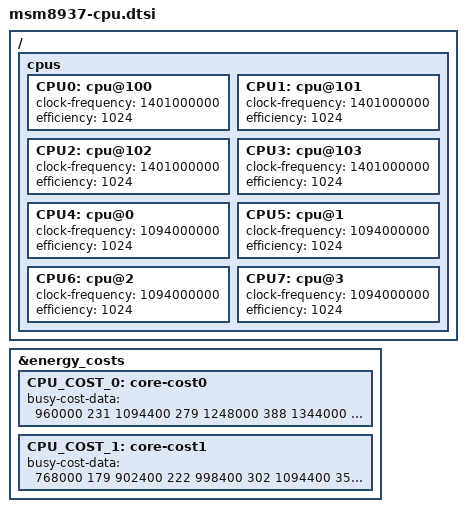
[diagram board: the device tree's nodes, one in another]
/{
	cpus {
  		CPU0: cpu@100 {
    			clock-frequency = <1401000000>;
    			efficiency = <1024>;
  		};
  		CPU1: cpu@101 {
    			clock-frequency = <1401000000>;
    			efficiency = <1024>;
  		};
  		CPU2: cpu@102 {
    			clock-frequency = <1401000000>;
    			efficiency = <1024>;
  		};
  		CPU3: cpu@103 {
    			clock-frequency = <1401000000>;
    			efficiency = <1024>;
  		};
  		CPU4: cpu@0 {
    			clock-frequency = <1094000000>;
    			efficiency = <1024>;
  		};
  		CPU5: cpu@1 {
    			clock-frequency = <1094000000>;
    			efficiency = <1024>;
  		};
  		CPU6: cpu@2 {
    			clock-frequency = <1094000000>;
    			efficiency = <1024>;
  		};
  		CPU7: cpu@3 {
    			clock-frequency = <1094000000>;
    			efficiency = <1024>;
  		};
	};
};

&energy_costs {
	CPU_COST_0: core-cost0 {
		busy-cost-data = <
			960000  231
			1094400  279
			1248000  388
			1344000  437
			1401000  465
			1497600  476
		>;
	};

  	CPU_COST_1: core-cost1 {
		busy-cost-data = <
			768000  179
			902400  222
			998400  302
			1094400  354
			1209600  376
		>;
	};
};
